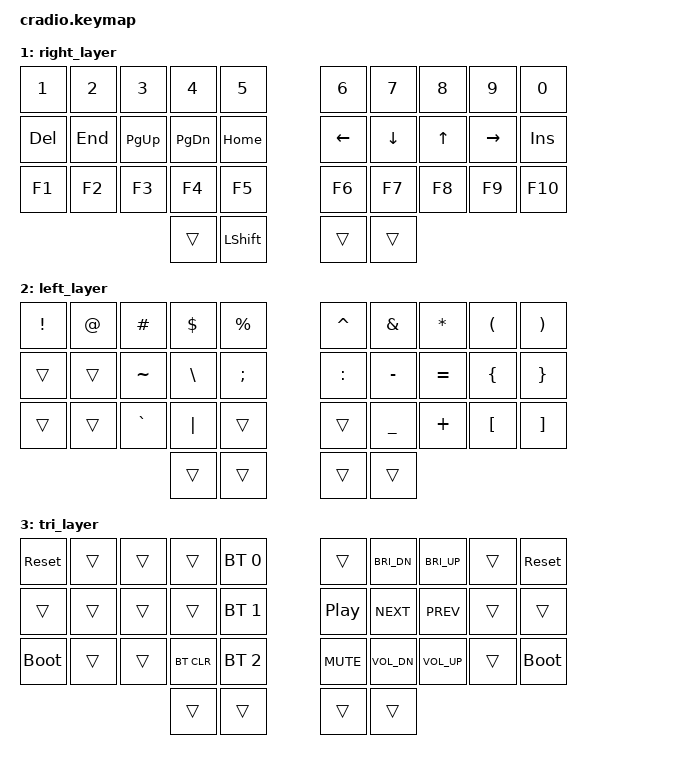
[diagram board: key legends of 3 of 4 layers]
// Copyright (c) 2022 The ZMK Contributors
// SPDX-License-Identifier: MIT

#include <behaviors.dtsi>
#include <dt-bindings/zmk/keys.h>
#include <dt-bindings/zmk/bt.h>

// Home row mods macro
#define HRML(k1,k2,k3,k4) &ht LCTRL k1  &ht LSHFT k2  &ht LGUI k3  &ht LALT k4
#define HRMR(k1,k2,k3,k4) &ht RALT k1  &ht RGUI k2  &ht RSHFT k3  &ht RCTRL k4

/ {
    behaviors {
        ht: hold_tap {
            compatible = "zmk,behavior-hold-tap";
            #binding-cells = <2>;
            flavor = "tap-preferred";
            tapping-term-ms = <220>;
            quick-tap-ms = <150>;
            require-prior-idle-ms = <100>;
            bindings = <&kp>, <&kp>;
        };
    };

    combos {
        compatible = "zmk,combos";
        combo_esc {
            timeout-ms = <50>;
            key-positions = <0 1>;
            bindings = <&kp ESC>;
        };
	combo_caps_word	{
	    timeout-ms = <50>;
	    key-positions = <11 18>;
	    bindings = <&caps_word>;
	};
    };

    conditional_layers {
        compatible = "zmk,conditional-layers";
        tri_layer {
            if-layers = <1 2>;
            then-layer = <3>;
        };
    };

    keymap {
        compatible = "zmk,keymap";
        default_layer {
            bindings = <
        //╭──────────┬──────────┬──────────┬──────────┬──────────╮   ╭──────────┬──────────┬──────────┬──────────┬──────────╮
        //│  Q       │  W       │  F       │  P       │  B       │   │  J       │  L       │  U       │  Y       │  '       │
            &kp Q      &kp W      &kp F      &kp P      &kp B          &kp J      &kp L      &kp U      &kp Y      &kp SQT
        //├──────────┼──────────┼──────────┼──────────┼──────────┤   ├──────────┼──────────┼──────────┼──────────┼──────────┤
        //│  A       │  R       │  S       │  T       │  G       │   │  M       │  N       │  E       │  I       │  O       │
            HRML(A,        R,         S,         T)     &kp G          &kp M      HRMR(N,        E,         I,        O)
        //├──────────┼──────────┼──────────┼──────────┼──────────┤   ├──────────┼──────────┼──────────┼──────────┼──────────┤
        //│  Z       │  X       │  C       │  D       │  V       │   │  K       │  H       │ , <      │ . >      │ / ?      │
            &kp Z      &kp X      &kp C      &kp D      &kp V          &kp K      &kp H      &kp COMMA  &kp DOT    &kp FSLH
        //╰──────────┴──────────┴──────────┼──────────┼──────────┤   ├──────────┼──────────┼──────────┴──────────┴──────────╯
                                            &lt 2 TAB   &kp SPACE     &kp ENTER  &lt 1 BSPC
        //                                 ╰──────────┴──────────╯   ╰──────────┴──────────╯
            >;
        };

        right_layer {
            bindings = <
        //╭──────────┬──────────┬──────────┬──────────┬──────────╮   ╭──────────┬──────────┬──────────┬──────────┬──────────╮
        //│  1       │  2       │  3       │  4       │  5       │   │ 6        │ 7        │ 8        │ 9        │  0       │
            &kp N1    &kp N2     &kp N3     &kp N4     &kp N5         &kp N6     &kp N7     &kp N8     &kp N9     &kp N0
        //├──────────┼──────────┼──────────┼──────────┼──────────┤   ├──────────┼──────────┼──────────┼──────────┼──────────┤
        //│ DELETE   │  END     │ PAGE UP  │ PAGE DN  │  HOME    │   │ LEFT     │ DOWN     │ UP       │ RIGHT    │  INSERT  │
            &kp DEL   &kp END    &kp PG_UP  &kp PG_DN  &kp HOME       &kp LEFT   &kp DOWN   &kp UP     &kp RIGHT  &kp INS
        //├──────────┼──────────┼──────────┼──────────┼──────────┤   ├──────────┼──────────┼──────────┼──────────┼──────────┤
        //│ F1       │  F2      │  F3      │  F4      │  F5      │   │  F6      │  F7      │  F8      │  F9      │  F10     │
           &kp F1     &kp F2     &kp F3     &kp F4     &kp F5         &kp F6     &kp F7     &kp F8     &kp F9     &kp F10
        //╰──────────┴──────────┴──────────┼──────────┼──────────┤   ├──────────┼──────────┼──────────┴──────────┴──────────╯
                                             &trans     &kp LSHFT     &trans     &trans
        //                                 ╰──────────┴──────────╯   ╰──────────┴──────────╯
            >;
        };

        left_layer {
            bindings = <
        //╭──────────┬──────────┬──────────┬──────────┬──────────╮   ╭──────────┬──────────┬──────────┬──────────┬──────────╮
        //│  !       │  @       │  #       │  $       │  %       │   │  ^       │  &       │  *       │  (       │  )       │
            &kp EXCL   &kp AT     &kp HASH   &kp DLLR   &kp PRCNT      &kp CARET &kp AMPS   &kp ASTRK  &kp LPAR   &kp RPAR
        //├──────────┼──────────┼──────────┼──────────┼──────────┤   ├──────────┼──────────┼──────────┼──────────┼──────────┤
        //│          │          │  ~       │  \       │  ;       │   │  :       │  -       │  =       │  {       │  }       │
            &trans     &trans    &kp TILDE  &kp BSLH   &kp SEMI       &kp COLON  &kp MINUS  &kp EQUAL  &kp LBRC   &kp RBRC
        //├──────────┼──────────┼──────────┼──────────┼──────────┤   ├──────────┼──────────┼──────────┼──────────┼──────────┤
        //│          │          │  `       │  |       │          │   │          │  _       │  +       │  [       │  ]       │
            &trans     &trans    &kp GRAVE  &kp PIPE   &trans         &trans     &kp UNDER  &kp PLUS   &kp LBKT   &kp RBKT
        //╰──────────┴──────────┴──────────┼──────────┼──────────┤   ├──────────┼──────────┼──────────┴──────────┴──────────╯
                                             &trans     &trans         &trans     &trans
        //                                 ╰──────────┴──────────╯   ╰──────────┴──────────╯
            >;
        };

        tri_layer {
            bindings = <
        //╭──────────┬──────────┬──────────┬──────────┬──────────╮   ╭──────────┬──────────┬──────────┬──────────┬──────────╮
        //│ RESET    │          │          │          │PROFILE 0 │   │          │ BRT DOWN │  BRT UP  │          │  RESET   │
          &sys_reset  &trans     &trans     &trans    &bt BT_SEL 0   &trans   &kp C_BRI_DN &kp C_BRI_UP  &trans   &sys_reset
        //├──────────┼──────────┼──────────┼──────────┼──────────┤   ├──────────┼──────────┼──────────┼──────────┼──────────┤
        //│          │          │          │          │PROFILE 1 │   │ PLAY/PAU │  NEXT    │  PREV    │          │          │
           &trans     &trans     &trans     &trans    &bt BT_SEL 1   &kp C_PP   &kp C_NEXT &kp C_PREV  &trans      &trans
        //├──────────┼──────────┼──────────┼──────────┼──────────┤   ├──────────┼──────────┼──────────┼──────────┼──────────┤
        //│BOOTLOADER│          │          │ CLEAR BT │PROFILE 2 │   │  MUTE    │ VOL DOWN │ VOL UP   │          │BOOTLOADER│
          &bootloader &trans     &trans    &bt BT_CLR &bt BT_SEL 2   &kp C_MUTE &kp C_VOL_DN &kp C_VOL_UP &trans   &bootloader
        //╰──────────┴──────────┴──────────┼──────────┼──────────┤   ├──────────┼──────────┼──────────┴──────────┴──────────╯
                                             &trans     &trans         &trans     &trans
        //                                 ╰──────────┴──────────╯   ╰──────────┴──────────╯
            >;
        };
    };
};
